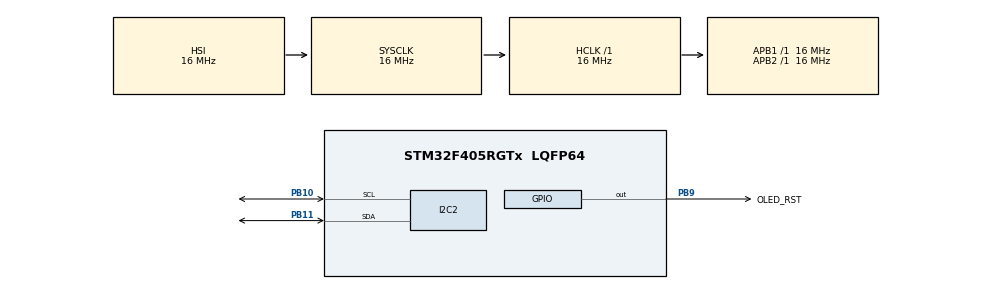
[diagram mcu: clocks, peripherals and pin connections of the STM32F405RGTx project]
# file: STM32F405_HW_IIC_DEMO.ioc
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Dma.I2C2_TX.0.Direction=DMA_MEMORY_TO_PERIPH
Dma.I2C2_TX.0.FIFOMode=DMA_FIFOMODE_DISABLE
Dma.I2C2_TX.0.Instance=DMA1_Stream7
Dma.I2C2_TX.0.MemDataAlignment=DMA_MDATAALIGN_BYTE
Dma.I2C2_TX.0.MemInc=DMA_MINC_ENABLE
Dma.I2C2_TX.0.Mode=DMA_NORMAL
Dma.I2C2_TX.0.PeriphDataAlignment=DMA_PDATAALIGN_BYTE
Dma.I2C2_TX.0.PeriphInc=DMA_PINC_DISABLE
Dma.I2C2_TX.0.Priority=DMA_PRIORITY_LOW
Dma.Request0=I2C2_TX
I2C2.I2C_Mode=I2C_Fast
Mcu.Family=STM32F4
Mcu.Name=STM32F405RGTx
Mcu.Package=LQFP64
NVIC.DMA1_Stream7_IRQn=true\:0\:0\:false\:false\:true\:false\:true\:true
NVIC.PriorityGroup=NVIC_PRIORITYGROUP_4
PB10.Mode=I2C
PB10.Signal=I2C2_SCL
PB11.Mode=I2C
PB11.Signal=I2C2_SDA
PB9.GPIO_Label=OLED_RST
PB9.GPIO_PuPd=GPIO_PULLUP
PB9.GPIO_Speed=GPIO_SPEED_FREQ_HIGH
PB9.PinState=GPIO_PIN_SET
PB9.Signal=GPIO_Output
PH0-OSC_IN.Mode=HSE-External-Oscillator
PH0-OSC_IN.Signal=RCC_OSC_IN
PH1-OSC_OUT.Mode=HSE-External-Oscillator
PH1-OSC_OUT.Signal=RCC_OSC_OUT
ProjectManager.HeapSize=0x200
ProjectManager.StackSize=0x400
ProjectManager.TargetToolchain=MDK-ARM V5.32
RCC.AHBFreq_Value=16000000
RCC.APB1Freq_Value=16000000
RCC.APB2Freq_Value=16000000
RCC.CortexFreq_Value=16000000
RCC.HSE_VALUE=25000000
RCC.HSI_VALUE=16000000
RCC.LSE_VALUE=32768
RCC.SYSCLKFreq_VALUE=16000000
RCC.VCOOutputFreq_Value=192000000
board=custom

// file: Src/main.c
/* USER CODE BEGIN Header */
/**
  ******************************************************************************
  * @file           : main.c
  * @brief          : Main program body
  ******************************************************************************
  * @attention
  *
  * Copyright (c) 2022 STMicroelectronics.
  * All rights reserved.
  *
  * This software is licensed under terms that can be found in the LICENSE file
  * in the root directory of this software component.
  * If no LICENSE file comes with this software, it is provided AS-IS.
  *
  ******************************************************************************
  */
/* USER CODE END Header */
#include "main.h"

/* USER CODE BEGIN Includes */
#include <string.h>
#include <stdio.h>
#include "oled.h"
#include "oled_hw.h"
/* USER CODE END Includes */

I2C_HandleTypeDef hi2c2;
DMA_HandleTypeDef hdma_i2c2_tx;

void SystemClock_Config(void);
static void MX_GPIO_Init(void);
static void MX_DMA_Init(void);
static void MX_I2C2_Init(void);

int main(void)
{
  /* USER CODE BEGIN 1 */
  uint32_t cnt=0,i2c_reset_cnt=0;
  char str[16]={0},str2[16]={0};

  /* USER CODE END 1 */

  /* MCU Configuration--------------------------------------------------------*/

  /* Reset of all peripherals, Initializes the Flash interface and the Systick. */
  HAL_Init();

  /* Configure the system clock */
  SystemClock_Config();

  /* Initialize all configured peripherals */
  MX_GPIO_Init();
  MX_DMA_Init();
  MX_I2C2_Init();
  /* USER CODE BEGIN 2 */

  oled_init();
  oled_clear();
  oled_show_string16(0,0,"HELLO WORLD");
  oled_refresh();
  HAL_Delay(1000);
  /* USER CODE END 2 */

  /* Infinite loop */
  while (1)
  {
    cnt++;
    i2c_reset_cnt = i2c_reset_cnt_get();
    snprintf(str, sizeof(str), "count:%u", cnt);
    snprintf(str2, sizeof(str2), "i2c reset:%u", i2c_reset_cnt);
    oled_clear();
    oled_show_string16(0, 10, str);
    oled_show_string12(0, 40, str2);
    oled_refresh();

    HAL_Delay(1000);
  }
}

void SystemClock_Config(void)
{
  RCC_OscInitTypeDef RCC_OscInitStruct = {0};
  RCC_ClkInitTypeDef RCC_ClkInitStruct = {0};

  /** Configure the main internal regulator output voltage
  */
  __HAL_RCC_PWR_CLK_ENABLE();
  __HAL_PWR_VOLTAGESCALING_CONFIG(PWR_REGULATOR_VOLTAGE_SCALE1);

  /** Initializes the RCC Oscillators according to the specified parameters
  * in the RCC_OscInitTypeDef structure.
  */
  RCC_OscInitStruct.OscillatorType = RCC_OSCILLATORTYPE_HSI;
  RCC_OscInitStruct.HSIState = RCC_HSI_ON;
  RCC_OscInitStruct.HSICalibrationValue = RCC_HSICALIBRATION_DEFAULT;
  RCC_OscInitStruct.PLL.PLLState = RCC_PLL_NONE;
  if (HAL_RCC_OscConfig(&RCC_OscInitStruct) != HAL_OK)
  {
    Error_Handler();
  }

  /** Initializes the CPU, AHB and APB buses clocks
  */
  RCC_ClkInitStruct.ClockType = RCC_CLOCKTYPE_HCLK|RCC_CLOCKTYPE_SYSCLK
                              |RCC_CLOCKTYPE_PCLK1|RCC_CLOCKTYPE_PCLK2;
  RCC_ClkInitStruct.SYSCLKSource = RCC_SYSCLKSOURCE_HSI;
  RCC_ClkInitStruct.AHBCLKDivider = RCC_SYSCLK_DIV1;
  RCC_ClkInitStruct.APB1CLKDivider = RCC_HCLK_DIV1;
  RCC_ClkInitStruct.APB2CLKDivider = RCC_HCLK_DIV1;

  if (HAL_RCC_ClockConfig(&RCC_ClkInitStruct, FLASH_LATENCY_0) != HAL_OK)
  {
    Error_Handler();
  }
}

static void MX_I2C2_Init(void)
{

  hi2c2.Instance = I2C2;
  hi2c2.Init.ClockSpeed = 400000;
  hi2c2.Init.DutyCycle = I2C_DUTYCYCLE_2;
  hi2c2.Init.OwnAddress1 = 0;
  hi2c2.Init.AddressingMode = I2C_ADDRESSINGMODE_7BIT;
  hi2c2.Init.DualAddressMode = I2C_DUALADDRESS_DISABLE;
  hi2c2.Init.OwnAddress2 = 0;
  hi2c2.Init.GeneralCallMode = I2C_GENERALCALL_DISABLE;
  hi2c2.Init.NoStretchMode = I2C_NOSTRETCH_DISABLE;
  if (HAL_I2C_Init(&hi2c2) != HAL_OK)
  {
    Error_Handler();
  }

}

static void MX_DMA_Init(void)
{

  /* DMA controller clock enable */
  __HAL_RCC_DMA1_CLK_ENABLE();

  /* DMA interrupt init */
  /* DMA1_Stream7_IRQn interrupt configuration */
  HAL_NVIC_SetPriority(DMA1_Stream7_IRQn, 0, 0);
  HAL_NVIC_EnableIRQ(DMA1_Stream7_IRQn);

}

static void MX_GPIO_Init(void)
{
  GPIO_InitTypeDef GPIO_InitStruct = {0};

  /* GPIO Ports Clock Enable */
  __HAL_RCC_GPIOH_CLK_ENABLE();
  __HAL_RCC_GPIOB_CLK_ENABLE();

  /*Configure GPIO pin Output Level */
  HAL_GPIO_WritePin(GPIOB, GPIO_PIN_9, GPIO_PIN_SET);

  /*Configure GPIO pin : PB9 */
  GPIO_InitStruct.Pin = GPIO_PIN_9;
  GPIO_InitStruct.Mode = GPIO_MODE_OUTPUT_PP;
  GPIO_InitStruct.Pull = GPIO_PULLUP;
  GPIO_InitStruct.Speed = GPIO_SPEED_FREQ_HIGH;
  HAL_GPIO_Init(GPIOB, &GPIO_InitStruct);

}

void Error_Handler(void)
{
  __disable_irq();
  while (1)
  {
  }
}
